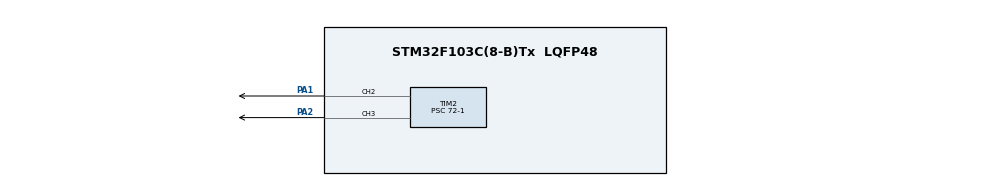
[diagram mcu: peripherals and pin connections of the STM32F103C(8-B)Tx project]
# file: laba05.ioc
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Mcu.Family=STM32F1
Mcu.Name=STM32F103C(8-B)Tx
Mcu.Package=LQFP48
NVIC.PriorityGroup=NVIC_PRIORITYGROUP_4
NVIC.RCC_IRQn=true\:0\:0\:false\:false\:true\:true\:false\:true
NVIC.TIM2_IRQn=true\:0\:0\:false\:true\:true\:1\:true\:true\:true
NVIC.TIM3_IRQn=true\:0\:0\:false\:true\:true\:2\:true\:true\:true
PA1.Signal=S_TIM2_CH2
PA2.Signal=S_TIM2_CH3
ProjectManager.HeapSize=0x200
ProjectManager.StackSize=0x400
ProjectManager.TargetToolchain=STM32CubeIDE
RCC.APB1Freq_Value=8000000
RCC.APB2Freq_Value=8000000
SH.S_TIM2_CH2.0=TIM2_CH2,PWM Generation2 CH2
SH.S_TIM2_CH3.0=TIM2_CH3,PWM Generation3 CH3
TIM2.Channel-PWM\ Generation2\ CH2=TIM_CHANNEL_2
TIM2.Channel-PWM\ Generation3\ CH3=TIM_CHANNEL_3
TIM2.Period=20000
TIM2.Prescaler=72-1
TIM2.Pulse-PWM\ Generation2\ CH2=100
TIM2.Pulse-PWM\ Generation3\ CH3=500
TIM2.TIM_MasterOutputTrigger=TIM_TRGO_RESET
TIM3.Period=100-1
TIM3.Prescaler=7200-1
TIM3.TIM_MasterOutputTrigger=TIM_TRGO_UPDATE
VP_SYS_VS_ND.Mode=No_Debug
VP_TIM2_VS_ClockSourceINT.Mode=Internal
VP_TIM3_VS_ClockSourceINT.Mode=Internal
board=custom

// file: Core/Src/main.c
/* USER CODE BEGIN Header */
/**
  ******************************************************************************
  * @file           : main.c
  * @brief          : Main program body
  ******************************************************************************
  * @attention
  *
  * Copyright (c) 2025 STMicroelectronics.
  * All rights reserved.
  *
  * This software is licensed under terms that can be found in the LICENSE file
  * in the root directory of this software component.
  * If no LICENSE file comes with this software, it is provided AS-IS.
  *
  ******************************************************************************
  */
/* USER CODE END Header */
#include "main.h"
#include "tim.h"
#include "gpio.h"

int angle1 = 500;
int angle2 = 2500;
int dir1 = 1;
int dir2 = -1;
int tick = 0;

void SystemClock_Config(void);
static void MX_NVIC_Init(void);

int main(void)
{
  HAL_Init();
  SystemClock_Config();
  MX_GPIO_Init();
  MX_TIM2_Init();
  MX_TIM3_Init();
  MX_NVIC_Init();

  /* USER CODE BEGIN 2 */
  HAL_TIM_PWM_Start(&htim2, TIM_CHANNEL_2); // PA1 - Серво 1
  HAL_TIM_PWM_Start(&htim2, TIM_CHANNEL_3); // PA2 - Серво 2

  __HAL_TIM_SET_COMPARE(&htim2, TIM_CHANNEL_2, angle1);
  __HAL_TIM_SET_COMPARE(&htim2, TIM_CHANNEL_3, angle2);

  HAL_TIM_Base_Start_IT(&htim3); // Запускаємо таймер з перериванням кожні 10 мс
  /* USER CODE END 2 */

  while (1)
  {
    // Основний цикл порожній, все керується в перериванні
  }
}

void SystemClock_Config(void)
{
  RCC_OscInitTypeDef RCC_OscInitStruct = {0};
  RCC_ClkInitTypeDef RCC_ClkInitStruct = {0};

  RCC_OscInitStruct.OscillatorType = RCC_OSCILLATORTYPE_HSI;
  RCC_OscInitStruct.HSIState = RCC_HSI_ON;
  RCC_OscInitStruct.HSICalibrationValue = RCC_HSICALIBRATION_DEFAULT;
  RCC_OscInitStruct.PLL.PLLState = RCC_PLL_NONE;
  if (HAL_RCC_OscConfig(&RCC_OscInitStruct) != HAL_OK)
  {
    Error_Handler();
  }

  RCC_ClkInitStruct.ClockType = RCC_CLOCKTYPE_HCLK|RCC_CLOCKTYPE_SYSCLK
                              |RCC_CLOCKTYPE_PCLK1|RCC_CLOCKTYPE_PCLK2;
  RCC_ClkInitStruct.SYSCLKSource = RCC_SYSCLKSOURCE_HSI;
  RCC_ClkInitStruct.AHBCLKDivider = RCC_SYSCLK_DIV1;
  RCC_ClkInitStruct.APB1CLKDivider = RCC_HCLK_DIV1;
  RCC_ClkInitStruct.APB2CLKDivider = RCC_HCLK_DIV1;

  if (HAL_RCC_ClockConfig(&RCC_ClkInitStruct, FLASH_LATENCY_0) != HAL_OK)
  {
    Error_Handler();
  }
}

/**
  * @brief NVIC Configuration.
  * @retval None
  */
static void MX_NVIC_Init(void)
{
  HAL_NVIC_SetPriority(TIM2_IRQn, 0, 0);
  HAL_NVIC_EnableIRQ(TIM2_IRQn);

  HAL_NVIC_SetPriority(TIM3_IRQn, 0, 0);
  HAL_NVIC_EnableIRQ(TIM3_IRQn);
}

/* USER CODE BEGIN 4 */
void HAL_TIM_PeriodElapsedCallback(TIM_HandleTypeDef *htim)
{
  if (htim->Instance == TIM3)
  {
    // Серво 1 — оновлення щоразу
    angle1 += dir1 * 10;
    if (angle1 >= 2500 || angle1 <= 500) dir1 *= -1;
    __HAL_TIM_SET_COMPARE(&htim2, TIM_CHANNEL_2, angle1);

    // Серво 2 — оновлення раз на 2 тики
    tick++;
    if (tick >= 2)
    {
      angle2 += dir2 * 10;
      if (angle2 >= 2500 || angle2 <= 500) dir2 *= -1;
      __HAL_TIM_SET_COMPARE(&htim2, TIM_CHANNEL_3, angle2);
      tick = 0;
    }
  }
}
/* USER CODE END 4 */

void Error_Handler(void)
{
  __disable_irq();
  while (1)
  {
  }
}
